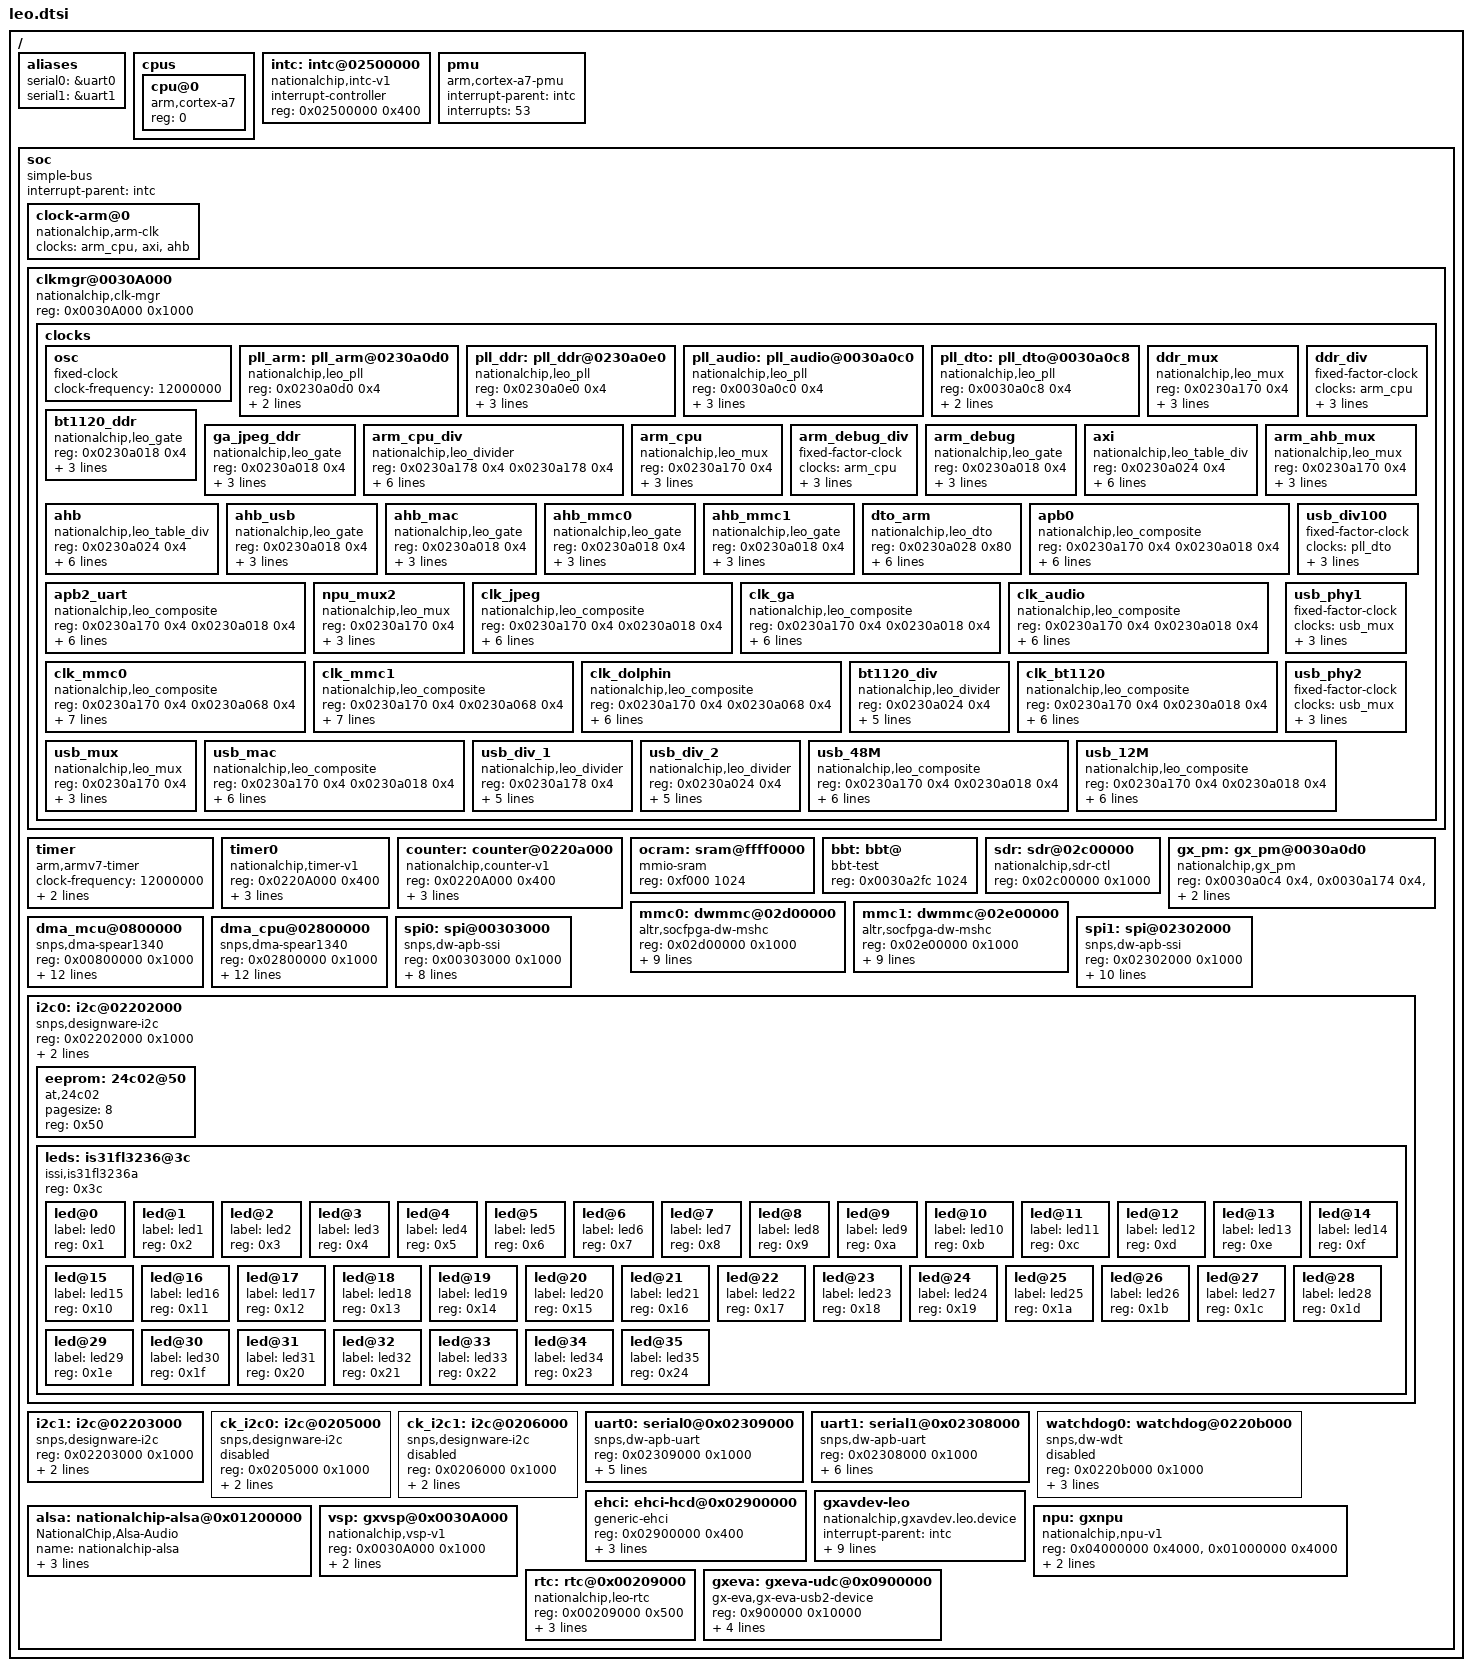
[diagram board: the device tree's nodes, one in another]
/*
 *  Copyright (C) 2012 Altera <www.altera.com>
 *
 * This program is free software; you can redistribute it and/or modify
 * it under the terms of the GNU General Public License as published by
 * the Free Software Foundation; either version 2 of the License, or
 * (at your option) any later version.
 *
 * This program is distributed in the hope that it will be useful,
 * but WITHOUT ANY WARRANTY; without even the implied warranty of
 * MERCHANTABILITY or FITNESS FOR A PARTICULAR PURPOSE.  See the
 * GNU General Public License for more details.
 *
 * You should have received a copy of the GNU General Public License
 * along with this program.  If not, see <http://www.gnu.org/licenses/>.
 */

#include "skeleton.dtsi"
#include "leo_pinctrl.dtsi"
#include <dt-bindings/reset/altr,rst-mgr.h>
#include <dt-bindings/input/linux-event-codes.h>

/ {
	#address-cells = <1>;
	#size-cells = <1>;

	aliases {
		serial0 = &uart0;
		serial1 = &uart1;
	};

	cpus {
		#address-cells = <1>;
		#size-cells = <0>;

		cpu@0 {
			compatible = "arm,cortex-a7";
			device_type = "cpu";
			reg = <0>;
		};
	};

	intc: intc@02500000 {
		compatible = "nationalchip,intc-v1";
		#interrupt-cells = <1>;
		interrupt-controller;
		reg = <0x02500000 0x400>;
	};

	pmu {
		compatible = "arm,cortex-a7-pmu";
		interrupt-parent = <&intc>;
		interrupts = <53>;
	};

	soc {
		#address-cells = <1>;
		#size-cells = <1>;
		compatible = "simple-bus";
		device_type = "soc";
		interrupt-parent = <&intc>;
		ranges;

		clock-arm@0 {
			compatible = "nationalchip,arm-clk";
			clocks = <&arm_cpu>, <&axi>, <&ahb>;
			clock-names = "arm-clk-cpu", "arm-clk-axi", "arm-clk-ahb";
		};

		clkmgr@0030A000 {
			compatible = "nationalchip,clk-mgr";
			reg = <0x0030A000 0x1000>;

			clocks {
				#address-cells = <1>;
				#size-cells = <0>;

				osc: osc {
					#clock-cells = <0>;
					compatible = "fixed-clock";
					clock-frequency = <12000000>;
				};

// PLL 配置

				pll_arm: pll_arm@0230a0d0{
					#clock-cells = <0>;
					compatible = "nationalchip,leo_pll";
					reg = <0x0230a0d0 0x4>;
					clocks = <&osc>;
					clock-output-names = "pll_arm";
				};

				pll_ddr: pll_ddr@0230a0e0{
					#clock-cells = <0>;
					compatible = "nationalchip,leo_pll";
					reg = <0x0230a0e0 0x4>;
					clocks = <&osc>;
					clock-output-names = "pll_ddr";
					clock-frequency = <216000000>;
				};

				pll_audio: pll_audio@0030a0c0{
					#clock-cells = <0>;
					compatible = "nationalchip,leo_pll";
					reg = <0x0030a0c0 0x4>;
					clocks = <&osc>;
					clock-output-names = "pll_audio";
					clock-frequency = <516000000>;
				};

				pll_dto: pll_dto@0030a0c8{
					#clock-cells = <0>;
					compatible = "nationalchip,leo_pll";
					reg = <0x0030a0c8 0x4>;
					clocks = <&osc>;
					clock-output-names = "pll_dto";
				};

// DDR PLL 时钟树
				ddr_mux: ddr_mux{
					#clock-cells = <0>;
					compatible = "nationalchip,leo_mux";
					reg = <0x0230a170 0x4>;
					mux_offset = <18>;
					clocks = <&osc>, <&pll_ddr>;
					clock-output-names = "ddr_mux";
				};

				ddr_div: ddr_div{
					compatible = "fixed-factor-clock";
					clocks = <&arm_cpu>;
					#clock-cells = <0>;
					clock-div  = <2>;
					clock-mult = <1>;
					clock-output-names = "ddr_div";
				};

				bt1120_ddr: bt1120_ddr{
					#clock-cells = <0>;
					compatible = "nationalchip,leo_gate";
					reg = <0x0230a018 0x4>;
					gate_bit = <18>;
					clocks = <&ddr_div>;
					clock-output-names = "bt1120_ddr";
				};

			/*	npu_ddr: npu_ddr{
					#clock-cells = <0>;
					compatible = "nationalchip,leo_gate";
					reg = <0x0230a018 0x4>;
					gate_bit = <16>;
					clocks = <&ddr_div>;
					clock-output-names = "npu_ddr";
				}; */

				ga_jpeg_ddr: ga_jpeg_ddr{
					#clock-cells = <0>;
					compatible = "nationalchip,leo_gate";
					reg = <0x0230a018 0x4>;
					gate_bit = <17>;
					clocks = <&ddr_div>;
					clock-output-names = "ga_jpeg_ddr";
				};

// ARM PLL 时钟树

				arm_cpu_div: arm_cpu_div{
					#clock-cells = <0>;
					compatible = "nationalchip,leo_divider";
					reg = <0x0230a178 0x4 0x0230a178 0x4>;
					clocks = <&pll_arm>;
					div_shift = <12>;
					div_width = <6>;
					div_base  = <1>;
					enable_shift = <20>;
					clock-output-names = "arm_cpu_div";
				};

				arm_cpu: arm_cpu{
					#clock-cells = <0>;
					compatible = "nationalchip,leo_mux";
					reg = <0x0230a170 0x4>;
					mux_offset = <0>;
					clocks = <&osc>, <&arm_cpu_div>;
					clock-output-names = "arm_cpu";
				};

				arm_debug_div: arm_debug_div{
					compatible = "fixed-factor-clock";
					clocks = <&arm_cpu>;
					#clock-cells = <0>;
					clock-div  = <8>;
					clock-mult = <1>;
					clock-output-names = "arm_debug_div";
				};

				arm_debug: arm_debug{
					#clock-cells = <0>;
					compatible = "nationalchip,leo_gate";
					reg = <0x0230a018 0x4>;
					gate_bit = <0>;
					clocks = <&arm_debug_div>;
					clock-output-names = "arm_debug";
				};

				axi:axi{
					#clock-cells = <0>;
					compatible = "nationalchip,leo_table_div";
					reg = <0x0230a024 0x4>;
					clk_ratio = <0 1 3 7 15>;
					clk_div   = <2 2 3 4  6>;
					div_shift = <0>;
					div_width = <4>;
					clocks = <&arm_cpu>;
					clock-output-names = "axi";
				};

				arm_ahb_mux: arm_ahb_mux{
					#clock-cells = <0>;
					compatible = "nationalchip,leo_mux";
					reg = <0x0230a170 0x4>;
					mux_offset = <17>;
					clocks = <&osc>, <&pll_arm>;
					clock-output-names = "arm_ahb_mux";
				};

				ahb:ahb{
					#clock-cells = <0>;
					compatible = "nationalchip,leo_table_div";
					reg = <0x0230a024 0x4>;
					clk_ratio = <0 1 3 7 15>;
					clk_div   = <2 2 3 8  6>;
					div_shift = <8>;
					div_width = <4>;
					clocks = <&pll_arm>;
					clock-output-names = "arm_ahb";
				};

				ahb_usb: ahb_usb{
					#clock-cells = <0>;
					compatible = "nationalchip,leo_gate";
					reg = <0x0230a018 0x4>;
					gate_bit = <1>;
					clocks = <&ahb>;
					clock-output-names = "ahb_usb";
				};

				ahb_mac: ahb_mac{
					#clock-cells = <0>;
					compatible = "nationalchip,leo_gate";
					reg = <0x0230a018 0x4>;
					gate_bit = <2>;
					clocks = <&ahb>;
					clock-output-names = "ahb_mac";
				};

				ahb_mmc0: ahb_mmc0{
					#clock-cells = <0>;
					compatible = "nationalchip,leo_gate";
					reg = <0x0230a018 0x4>;
					gate_bit = <3>;
					clocks = <&ahb>;
					clock-output-names = "ahb_mmc0";
				};

				ahb_mmc1: ahb_mmc1{
					#clock-cells = <0>;
					compatible = "nationalchip,leo_gate";
					reg = <0x0230a018 0x4>;
					gate_bit = <4>;
					clocks = <&ahb>;
					clock-output-names = "ahb_mmc1";
				};

// AUDIO PLL 时钟树


// DTO PLL 时钟树
				dto_arm: dto_arm{
					#clock-cells = <1>;
					compatible = "nationalchip,leo_dto";
					reg = <0x0230a028 0x80>;
					clocks = <&pll_dto>;
					clock-indices = <0>, <1>,
									<2>, <3>,
									<4>, <5>,
									<6>, <7>,
									<8>, <9>;
					clock-output-names = "dto_reserv",    "dto_arm_apb2_0",
										 "dto_arm_uart",  "dto_arm_npu",
										 "dto_arm_jpeg",  "dto_arm_ga",
										 "dto_arm_audio", "dto_arm_mmc0",
										 "dto_arm_mmc1",  "dto_arm_dolphin";
					};

				apb0: apb0{
					#clock-cells = <0>;
					compatible = "nationalchip,leo_composite";
					reg = <0x0230a170 0x4 0x0230a018 0x4>;
					clocks = <&osc>, <&dto_arm 1>;
					mux_offset = <1>;
					clock_div  = <1>;
					clock_mult = <1>;
					gate_bit   = <5>;
					clock-output-names = "apb0";
				};

				apb2_uart: apb2_uart{
					#clock-cells = <0>;
					compatible = "nationalchip,leo_composite";
					reg = <0x0230a170 0x4 0x0230a018 0x4>;
					clocks = <&osc>, <&dto_arm 2>;
					mux_offset = <2>;
					clock_div  = <1>;
					clock_mult = <1>;
					gate_bit   = <6>;
					clock-output-names = "apb2_uart";
				};

				npu_mux2: npu_mux2{
					#clock-cells = <0>;
					compatible = "nationalchip,leo_mux";
					reg = <0x0230a170 0x4>;
					mux_offset = <24>;
					clocks = <&dto_arm 3>, <&pll_audio>;
					clock-output-names = "arm_npu2";
				};

				/* clk_npu: clk_npu{
					#clock-cells = <0>;
					compatible = "nationalchip,leo_composite";
					reg = <0x0230a170 0x4 0x0230a018 0x4>;
					clocks = <&osc>, <&npu_mux2>;
					mux_offset = <3>;
					clock_div  = <1>;
					clock_mult = <1>;
					gate_bit   = <15>;
					clock-output-names = "clk_npu";
				}; */

				clk_jpeg: clk_jpeg{
					#clock-cells = <0>;
					compatible = "nationalchip,leo_composite";
					reg = <0x0230a170 0x4 0x0230a018 0x4>;
					clocks = <&osc>, <&dto_arm 4>;
					mux_offset = <4>;
					clock_div  = <1>;
					clock_mult = <1>;
					gate_bit   = <7>;
					clock-output-names = "clk_jpeg";
				};

				clk_ga: clk_ga{
					#clock-cells = <0>;
					compatible = "nationalchip,leo_composite";
					reg = <0x0230a170 0x4 0x0230a018 0x4>;
					clocks = <&osc>, <&dto_arm 5>;
					mux_offset = <5>;
					clock_div  = <1>;
					clock_mult = <1>;
					gate_bit   = <8>;
					clock-output-names = "clk_ga";
				};

				clk_audio: clk_audio{
					#clock-cells = <0>;
					compatible = "nationalchip,leo_composite";
					reg = <0x0230a170 0x4 0x0230a018 0x4>;
					clocks = <&osc>, <&dto_arm 6>;
					mux_offset = <6>;
					clock_div  = <1>;
					clock_mult = <1>;
					gate_bit   = <9>;
					clock-output-names = "clk_audio";
				};

				clk_mmc0: clk_mmc0{
					#clock-cells = <0>;
					compatible = "nationalchip,leo_composite";
					reg = <0x0230a170 0x4 0x0230a068 0x4>;
					clocks = <&osc>, <&dto_arm 7>;
					mux_offset = <21>;
					clock_div  = <2>;
					clock_mult = <1>;
					gate_bit   = <16>;
					gate_width = <3>;
					clock-output-names = "clk_mmc0";
				};

				clk_mmc1: clk_mmc1{
					#clock-cells = <0>;
					compatible = "nationalchip,leo_composite";
					reg = <0x0230a170 0x4 0x0230a068 0x4>;
					clocks = <&osc>, <&dto_arm 8>;
					mux_offset = <22>;
					clock_div  = <2>;
					clock_mult = <1>;
					gate_bit   = <20>;
					gate_width = <3>;
					clock-output-names = "clk_mmc1";
				};

				clk_dolphin: clk_dolphin{
					#clock-cells = <0>;
					compatible = "nationalchip,leo_composite";
					reg = <0x0230a170 0x4 0x0230a068 0x4>;
					clocks = <&osc>, <&dto_arm 9>;
					mux_offset = <15>;
					clock_div  = <1>;
					clock_mult = <1>;
					gate_bit   = <15>;
					clock-output-names = "clk_dolphin";
				};

				bt1120_div: bt1120_div{
					#clock-cells = <0>;
					compatible = "nationalchip,leo_divider";
					reg = <0x0230a024 0x4>;
					clocks = <&pll_dto>;
					div_shift = <12>;
					div_width = <6>;
					div_base  = <1>;
					clock-output-names = "bt1120_div";
				};

				clk_bt1120: clk_bt1120{
					#clock-cells = <0>;
					compatible = "nationalchip,leo_composite";
					reg = <0x0230a170 0x4 0x0230a018 0x4>;
					clocks = <&osc>, <&bt1120_div>;
					mux_offset = <12>;
					clock_div  = <1>;
					clock_mult = <1>;
					gate_bit   = <14>;
					clock-output-names = "clk_bt1120";
				};

				usb_div100: usb_div100{
					compatible = "fixed-factor-clock";
					clocks = <&pll_dto>;
					#clock-cells = <0>;
					clock-div = <100>;
					clock-mult = <1>;
					clock-output-names = "usb_div100";
				};

				usb_mux: usb_mux{
					#clock-cells = <0>;
					compatible = "nationalchip,leo_mux";
					reg = <0x0230a170 0x4>;
					mux_offset = <7>;
					clocks = <&osc>, <&usb_div100>;
					clock-output-names = "usb_mux";
				};

				usb_phy1: usb_phy1{
					compatible = "fixed-factor-clock";
					clocks = <&usb_mux>;
					#clock-cells = <0>;
					clock-div  = <1>;
					clock-mult = <5>;
					clock-output-names = "usb_phy1";
				};

				usb_mac: usb_mac{
					#clock-cells = <0>;
					compatible = "nationalchip,leo_composite";
					reg = <0x0230a170 0x4 0x0230a018 0x4>;
					clocks = <&osc>, <&usb_phy1>;
					mux_offset = <8>;
					clock_div  = <1>;
					clock_mult = <1>;
					gate_bit   = <11>;
					clock-output-names = "usb_mac";
				};

				usb_phy2: usb_phy2{
					compatible = "fixed-factor-clock";
					clocks = <&usb_mux>;
					#clock-cells = <0>;
					clock-div  = <1>;
					clock-mult = <40>;
					clock-output-names = "usb_phy2";
				};

				usb_div_1: usb_div_1{
					#clock-cells = <0>;
					compatible = "nationalchip,leo_divider";
					reg = <0x0230a178 0x4>;
					clocks = <&usb_phy2>;
					div_shift = <24>;
					div_width = <6>;
					div_base  = <1>;
					clock-output-names = "usb_div_1";
				};

				usb_div_2: usb_div_2{
					#clock-cells = <0>;
					compatible = "nationalchip,leo_divider";
					reg = <0x0230a024 0x4>;
					clocks = <&usb_div_1>;
					div_shift = <24>;
					div_width = <6>;
					div_base  = <1>;
					clock-output-names = "usb_div_2";
				};

				usb_48M: usb_48M{
					#clock-cells = <0>;
					compatible = "nationalchip,leo_composite";
					reg = <0x0230a170 0x4 0x0230a018 0x4>;
					clocks = <&osc>, <&usb_div_1>;
					mux_offset = <10>;
					clock_div  = <1>;
					clock_mult = <1>;
					gate_bit   = <12>;
					clock-output-names = "usb_48M";
				};

				usb_12M: usb_12M{
					#clock-cells = <0>;
					compatible = "nationalchip,leo_composite";
					reg = <0x0230a170 0x4 0x0230a018 0x4>;
					clocks = <&osc>, <&usb_div_2>;
					mux_offset = <11>;
					clock_div  = <1>;
					clock_mult = <1>;
					gate_bit   = <13>;
					clock-output-names = "usb_12M";
				};
			};
		};

		timer {
		    compatible = "arm,armv7-timer";
		    clock-frequency = <12000000>;
		    interrupt-parent = <&intc>;
		    interrupts = <17>, <16>, <19>, <18>;
		};
		timer0 {
			compatible = "nationalchip,timer-v1";
			reg = <0x0220A000 0x400>;
			clock-frequency = <54000000>;
			interrupt-parent = <&intc>;
			interrupts = <5>;
		};

		counter: counter@0220a000 {
			compatible = "nationalchip,counter-v1";
			reg = <0x0220A000 0x400>;
			clocks = <&apb0>;
			interrupt-parent = <&intc>;
			interrupts = <5>, <6>, <7>, <8>;
		};

		ocram: sram@ffff0000 {
			compatible = "mmio-sram";
			reg = <0xf000 1024>;
		};

		bbt: bbt@{
			compatible = "bbt-test";
			reg = <0x0030a2fc 1024>;
		};

		sdr: sdr@02c00000 {
			compatible = "nationalchip,sdr-ctl";
			reg = <0x02c00000 0x1000>;
		};

		gx_pm: gx_pm@0030a0d0 {
			compatible = "nationalchip,gx_pm";
			reg = <0x0030a0c4 0x4>, <0x0030a174 0x4>, <0x0030a268 12>;
			cpu_int_chan = <30>;
		};


		mmc0: dwmmc@02d00000 {
			compatible = "altr,socfpga-dw-mshc";
			reg = <0x02d00000 0x1000>;
			interrupt-parent = <&intc>;
			interrupts = <43>;
			fifo-depth = <0x200>;
			#address-cells = <1>;
			#size-cells = <0>;

			num-slots = <1>;
			broken-cd;
			bus-width = <4>;
			cap-mmc-highspeed;
			cap-sd-highspeed;

			clocks = <&ahb_mmc0>, <&clk_mmc0>;
			clock-names = "biu", "ciu";

			status = "okay";
		};

		mmc1: dwmmc@02e00000 {
			compatible = "altr,socfpga-dw-mshc";
			reg = <0x02e00000 0x1000>;
			interrupt-parent = <&intc>;
			interrupts = <44>;
			fifo-depth = <0x200>;
			#address-cells = <1>;
			#size-cells = <0>;

			num-slots = <1>;
			broken-cd;
			bus-width = <4>;
			cap-mmc-highspeed;
			cap-sd-highspeed;

			clocks = <&ahb_mmc1>, <&clk_mmc1>;
			clock-names = "biu", "ciu";

			status = "okay";
		};

		dma_mcu@0800000 {
			compatible = "snps,dma-spear1340";
			reg = <0x00800000 0x1000>;
			interrupt-parent = <&intc>;
			interrupts = <30>;
			dma-requests = <32>;
			dma-channels = <4>;
			dma-masters  = <4>;
			#dma-cells   = <3>;
			chan_allocation_order = <0>;
			chan_priority = <1>;
			block_size = <0xFFF>;
			data_width = <2 2 2 2>;
			clocks = <&ahb>;
			clock-names = "hclk";
			is_private;
			is_memcpy;
			status = "okay";
		};

		dma_cpu@02800000 {
			compatible = "snps,dma-spear1340";
			reg = <0x02800000 0x1000>;
			interrupt-parent = <&intc>;
			interrupts = <10>;
			dma-requests = <32>;
			dma-channels = <4>;
			dma-masters  = <4>;
			#dma-cells   = <3>;
			chan_allocation_order = <0>;
			chan_priority = <1>;
			block_size = <0xFFF>;
			data_width = <2 2 2 2>;
			clocks = <&ahb>;
			clock-names = "hclk";
			is_private;
			is_memcpy;
			status = "okay";
		};

		spi0: spi@00303000 {
			compatible = "snps,dw-apb-ssi";
			#address-cells = <1>;
			#size-cells = <0>;
			reg = <0x00303000 0x1000>;
			interrupt-parent = <&intc>;
			interrupts = <25>;
			poll-mode = <1>;
			sample-dly = <2>;
			/* 选择使用哪个dma控制器, 为上面dma设备树的名称*/
			dma_ctrl_name = "dma_mcu";
			num-cs = <4>;
			clocks = <&ahb>;
			cs-reg = <0x30a168>;
			status = "okay";
		};

		spi1: spi@02302000 {
			compatible = "snps,dw-apb-ssi";
			#address-cells = <1>;
			#size-cells = <0>;
			reg = <0x02302000 0x1000>;
			interrupt-parent = <&intc>;
			interrupts = <11>;
			num-cs = <4>;
			clocks = <&ahb>;
			cs-reg = <0x230a600>;
			bus-num = <0>;
			poll-mode = <1>;
			sample-dly = <2>;
			reg-io-width = <1>;
			/* 选择使用哪个dma控制器, 为上面dma设备树的名称*/
			dma_ctrl_name = "dma_cpu";
			status = "okay";
		};

		i2c0: i2c@02202000 {
			#address-cells = <1>;
			#size-cells = <0>;
			compatible = "snps,designware-i2c";
			reg = <0x02202000 0x1000>;
			clocks = <&apb0>;
			interrupts = <1>;
			status = "okay";

			eeprom: 24c02@50 {
				compatible = "at,24c02";
				pagesize = <8>;
				reg = <0x50>;
			};
			leds: is31fl3236@3c {
				compatible = "issi,is31fl3236a";
				#address-cells = <1>;
				#size-cells = <0>;
				reg = <0x3c>;

				led@0 {
					label = "led0";
					reg = <0x1>;
				};

				led@1 {
					label = "led1";
					reg = <0x2>;
				};

				led@2 {
					label = "led2";
					reg = <0x3>;
				};

				led@3 {
					label = "led3";
					reg = <0x4>;
				};

				led@4 {
					label = "led4";
					reg = <0x5>;
				};

				led@5 {
					label = "led5";
					reg = <0x6>;
				};

				led@6 {
					label = "led6";
					reg = <0x7>;
				};

				led@7 {
					label = "led7";
					reg = <0x8>;
				};

				led@8 {
					label = "led8";
					reg = <0x9>;
				};

				led@9 {
					label = "led9";
					reg = <0xa>;
				};

				led@10 {
					label = "led10";
					reg = <0xb>;
				};

				led@11 {
					label = "led11";
					reg = <0xc>;
				};

				led@12 {
					label = "led12";
					reg = <0xd>;
				};

				led@13 {
					label = "led13";
					reg = <0xe>;
				};

				led@14 {
					label = "led14";
					reg = <0xf>;
				};

				led@15 {
					label = "led15";
					reg = <0x10>;
				};

				led@16 {
					label = "led16";
					reg = <0x11>;
				};

				led@17 {
					label = "led17";
					reg = <0x12>;
				};

				led@18 {
					label = "led18";
					reg = <0x13>;
				};

				led@19 {
					label = "led19";
					reg = <0x14>;
				};

				led@20 {
					label = "led20";
					reg = <0x15>;
				};

				led@21 {
					label = "led21";
					reg = <0x16>;
				};

				led@22 {
					label = "led22";
					reg = <0x17>;
				};

				led@23 {
					label = "led23";
					reg = <0x18>;
				};

				led@24 {
					label = "led24";
					reg = <0x19>;
				};

				led@25 {
					label = "led25";
					reg = <0x1a>;
				};

				led@26 {
					label = "led26";
					reg = <0x1b>;
				};

				led@27 {
					label = "led27";
					reg = <0x1c>;
				};

				led@28 {
					label = "led28";
					reg = <0x1d>;
				};

				led@29 {
					label = "led29";
					reg = <0x1e>;
				};

				led@30 {
					label = "led30";
					reg = <0x1f>;
				};

				led@31 {
					label = "led31";
					reg = <0x20>;
				};

				led@32 {
					label = "led32";
					reg = <0x21>;
				};

				led@33 {
					label = "led33";
					reg = <0x22>;
				};

				led@34 {
					label = "led34";
					reg = <0x23>;
				};

				led@35 {
					label = "led35";
					reg = <0x24>;
				};
			};
		};

		i2c1: i2c@02203000 {
			#address-cells = <1>;
			#size-cells = <0>;
			compatible = "snps,designware-i2c";
			reg = <0x02203000 0x1000>;
			clocks = <&apb0>;
			interrupts = <2>;
			status = "okay";
		};

		ck_i2c0: i2c@0205000 {
			#address-cells = <1>;
			#size-cells = <0>;
			compatible = "snps,designware-i2c";
			reg = <0x0205000 0x1000>;
			clocks = <&apb0>;
			interrupts = <23>;
			status = "disable";
		};

		ck_i2c1: i2c@0206000 {
			#address-cells = <1>;
			#size-cells = <0>;
			compatible = "snps,designware-i2c";
			reg = <0x0206000 0x1000>;
			clocks = <&apb0>;
			interrupts = <24>;
			status = "disable";
		};

		uart0: serial0@0x02309000 {
			compatible = "snps,dw-apb-uart";
			reg = <0x02309000 0x1000>;
			interrupt-parent = <&intc>;
			interrupts = <15>;
			reg-shift = <2>;
			reg-io-width = <4>;
			clocks = <&apb2_uart>;
		};

		uart1: serial1@0x02308000 {
			compatible = "snps,dw-apb-uart";
			reg = <0x02308000 0x1000>;
			interrupt-parent = <&intc>;
			interrupts = <14>;
			reg-shift = <2>;
			reg-io-width = <4>;
			cts-override;
			clocks = <&apb2_uart>;
		};

		watchdog0: watchdog@0220b000 {
			compatible = "snps,dw-wdt";
			reg = <0x0220b000 0x1000>;
			interrupt-parent = <&intc>;
			interrupts = <9>;
			clocks = <&ahb>;
			status = "disabled";
		};

		ehci: ehci-hcd@0x02900000 {
		  compatible = "generic-ehci";
		  reg = <0x02900000 0x400>;
		  clocks = <&usb_mac>,<&ahb_usb>;
		  clock-names = "usb_mac","ahb_usb";
		  interrupt-parent = <&intc>;
		  interrupts = <59>;
		};

		/*ohci: ohci-hcd@0x02a00000 {
		  compatible = "generic-ohci";
		  reg = <0x02a00000 0x400>;
		  clocks = <&usb_48M>,<&usb_12M>,<&usb_mac>,<&ahb_usb>;
		  clock-names = "usb_48m","usb_12m","usb_mac","ahb_usb";
		  interrupt-parent = <&intc>;
		  interrupts = <58>;
		};*/

		alsa: nationalchip-alsa@0x01200000 {
			name = "nationalchip-alsa";
			compatible  = "NationalChip,Alsa-Audio";
			#address-cells = <1>;
			#size-cells = <1>;
			reg = <0x01200000 0xf4>,
				<0x0030a1a0 0xc>,
				<0x0030a274 0x8>;
			reg-names = "gx8010.aout.opt.regs",
				"gx8010.aout.lodec.regs",
				"gx8010.aout.irq.regs";
			interrupts = <49>;
			interrupt-names = "gx8010.aout.irqs";
			status = "okay";
		};

		gxavdev-leo {
			compatible  = "nationalchip,gxavdev.leo.device";
			interrupt-parent = <&intc>;
			#address-cells = <1>;
			#size-cells = <1>;
			clocks = <&clk_jpeg>,
				<&clk_ga>,
				<&ga_jpeg_ddr>,
				<&clk_bt1120>,
				<&bt1120_div>,
				<&bt1120_ddr>,
				<&clk_audio>;
			clock-names = "gxavdev.jpeg.clk",
				"gxavdev.ga.clk",
				"gxavdev.ga_jpeg_ddr.clk",
				"gxavdev.bt1120.clk",
				"gxavdev.bt1120_div.clk",
				"gxavdev.bt1120_ddr.clk",
				"gxavdev.adec.clk";
			reg = <0x01200000 0xf4>,
				<0x0030a1a0 0xc>,
				<0x0030a018 0x4>,
				<0x0030a274 0x8>,
				<0x04600100 0xe8>,
				<0x04400000 0xd4>,
				<0x04400000 0xd4>,
				<0x04400200 0x30>,
				<0x0230a000 0x4>,
				<0x04d00000 0x1bc>;
			reg-names = "gxavdev.aout.opt.regs",
				"gxavdev.aout.lodac.regs",
				"gxavdev.aout.clock.regs",
				"gxavdev.aout.irq.regs",
				"gxavdev.adec.opt.regs",
				"gxavdev.jpeg.enc.regs",
				"gxavdev.jpeg.dec.regs",
				"gxavdev.jpeg.prp.regs",
				"gxavdev.jpeg.reset.regs",
				"gxavdev.bt1120.regs";
			interrupts = <49>,
						<36>,
						<36>,
						<37>,
						<47>;
			interrupt-names = "gxavdev.aout.irqs",
							"gxavdev.jpeg.enc.irqs",
							"gxavdev.jpeg.dec.irqs",
							"gxavdev.adec.irqs",
							"gxavdev.bt1120.irqs";
			status = "okay";
		};

		npu: gxnpu {
			compatible = "nationalchip,npu-v1";
			reg = <0x04000000 0x4000>, <0x01000000 0x4000>;
			interrupt-parent = <&intc>;
			interrupts = <33>, <40>;
		};

		vsp: gxvsp@0x0030A000 {
			compatible = "nationalchip,vsp-v1";
			reg = <0x0030A000 0x1000>;
			interrupt-parent = <&intc>;
			interrupts = <34>;
		};

		rtc: rtc@0x00209000 {
			compatible = "nationalchip,leo-rtc";
			reg = <0x00209000 0x500>;
			clocks = <&osc>;
			interrupt-parent = <&intc>;
			interrupts = <31>;
        };

		gxeva: gxeva-udc@0x0900000 {
		  compatible = "gx-eva,gx-eva-usb2-device";
		  reg = <0x900000 0x10000>;
		  #interrupt-parent = <&intc>;
		  interrupts = <50>, <51>, <52>;
		  eva,has-builtin-dma;
		  clocks = <&ahb>;
		  clock-names = "hclk";
		};
	};
};
